# ESM_ESM_52D00000h register map
Vendor: Texas Instruments
Peripheral module from a debugger description file (folder AM263P).
Registers are 32-bit, access not given, reset 0x0 unless marked. A register's access mark holds for its fields unless they carry their own. Offsets are as the file gives them; lines under a group give offsets from that group; [hi:lo] are bit positions; {n}, {i} and the like mark numbered series; 'fields as' and 'values as' point back to an identical list; <NAME> marks a mode.

## ESM
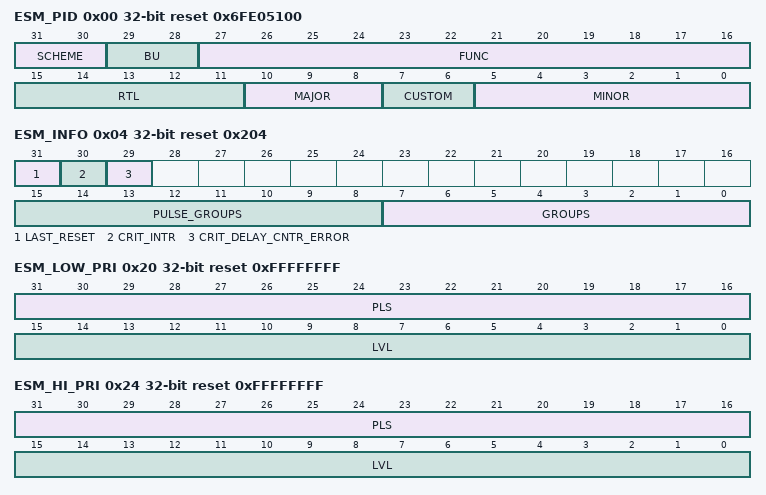
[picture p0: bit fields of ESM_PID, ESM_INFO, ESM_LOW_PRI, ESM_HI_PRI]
0x00 ESM_PID ro reset 0x6FE05100 — The Revision Register contains the major and minor revisions for the module.
  [31:30] SCHEME — PID register scheme
  [29:28] BU — Business Unit: 10 = Processors
  [27:16] FUNC — Module ID
  [15:11] RTL — RTL revision. Will vary depending on release.
  [10:8] MAJOR — Major revision
  [7:6] CUSTOM
  [5:0] MINOR — Minor revision
0x04 ESM_INFO ro reset 0x204 — The Info Register gives the configuration Inforrmation of this ESM.
  [31] LAST_RESET — Indicates the Source of the last Reset
  [30] CRIT_INTR — Indicates if the critical priority interrupt output has asserted
  [29] CRIT_DELAY_CNTR_ERROR — Indicates if a bit error has occurred in the critical priority interrupt delay counter
  [15:8] PULSE_GROUPS — Number of Pulse Error Groups
  [7:0] GROUPS — Total number of Error Groups
0x08 ESM_EN rw — The Global Enable Register has the master interrupt mask.
  [3:0] KEY — Global Enable. This field is a global mask to all interrupts. It is reset by the warm reset. The purpose is to leave all of the raw status and per-interrupt enable bits alone so that, after a warm reset, software may observe the state of the ESM before the warm reset and try to debug what may have caused the reset. 0x0: All events are disabled 0xF: All events are enabled All others are invalid
0x0C ESM_SFT_RST wo — The Global Soft Reset Register controls the global clear for raw status and enables.
  [3:0] KEY — Global Soft Reset. Writing to this field can cause all of the raw status and all enables to be cleared. This can be used to reset the ESM state after debugging because of a warm reset. Write: 0xF: Clear all raw status and enable bits All others no effect Read: Always read as 0x0
0x10 ESM_ERR_RAW — Raw Status/Set Register for Configuration Errors.
  [3:0] STS — This is the raw status for config errors. This is the raw status for errors in the configuration for Group N. This field is only reset by a Power-On-Reset and not by warm reset. A global soft reset will set this field to 0 Read: 0x0:Inactive 0x1:Active/Pending Write 0x1 to set event raw status Bits associated with groups that are not implemented in a certain configuration are Reserved, Read as 0 and writes will have no effect. (access R/W1TS)
0x14 ESM_ERR_STS — Config Error Enable and Clear Register.
  [3:0] MSK — This is the masked status/clear for config errors. This is the masked status for errors in the configuration for Group N. This field is only reset by a Power-On-Reset (not warm reset). A global soft reset will set this field to 0. Read: 0x0:Inactive 0x1:Active/Pending and Enabled Write 0x1 to clear event raw status. Bits associated with groups that are not implemented in a certain configuration are Reserved, Read as 0 and writes will have no effect. (access R/W1TC)
0x18 ESM_ERR_EN_SET — Config Error Enable Set Register.
  [3:0] MSK — This is the mask enable set for config errors. This is the mask enable for errors in the configuration for Group N. If the corresponding bit and the global_enable are set, then then interrupt is unmasked. This field is only reset by a Power-On-Reset (not warm reset). A global soft reset will set this field to 0. Read: 0x0:Disabled 0x1:Enabled Write 1'b1 to set enable Bits associated with groups that are not implemented in a certain configuration are Reserved, Read as 0 and writes will have no effect. (access R/W1TS)
0x1C ESM_ERR_EN_CLR — Config Error Interrupt Enabled Clear register.
  [3:0] MSK — This is the mask enable clear for config errors. This is the mask clear for errors in the configuration for Group N. If the corresponding bit and the global_enable are set, then then interrupt is unmasked. This field is only reset by a Power-On-Reset (not warm reset). A global soft reset will set this field to 0. Read: 0x0:Disabled 0x1:Enabled Write 1'b1 to clear enable Bits associated with groups that are not implemented in a certain configuration are Reserved, Read as 0 and writes will have no effect. (access R/W1TC)
0x20 ESM_LOW_PRI ro reset 0xFFFFFFFF — Shows which is the highest priority outstanding low priority interrupt.
  [31:16] PLS — This is the highest priority outstanding low priority pulse interrupt. Indicates what the highest priority Low Priority interrupt caused by a pulse number is. The lowest event has the highest priority. i.e. if Global Events 0, 1, 2, 3, and 4 are pending, and Global Event 0, and are configured for High Priority while Global Events 2, 3, and 4 are configured for Low Priority, then the value of this field will be 0x2. value of all ones (0xFFFF) indicates that there are no low priority interrupts pending. This field is updated whenever a new, higher priority event comes in. Software cannot read this field multiple times during an interrupt service routine to keep track of which interrupt is being serviced, because this field may have been updated with a higher priority event.
  [15:0] LVL — This is the highest priority outstanding low priority level interrupt. Indicates what the highest priority Low Priority interrupt caused by a level number is. The lowest event has the highest priority. i.e. if Global Events 0, 1, 2, 3, and 4 are pending, and Global Event 0, and are configured for High Priority while Global Events 2, 3, and 4 are configured for Low Priority, then the value of this field will be 0x2. value of all ones (0xFFFF) indicates that there are no low priority interrupts pending. This field is updated whenever a new, higher priority event comes in. Software cannot read this field multiple times during an interrupt service routine to keep track of which interrupt is being serviced, because this field may have been updated with a higher priority event.
0x24 ESM_HI_PRI ro reset 0xFFFFFFFF — Shows which is the highest priority outstanding high priority interrupt.
  [31:16] PLS — This is the highest priority outstanding high priority pulse interrupt. Indicates what the highest priority High Priority interrupt caused by a pulse number is. The lowest event has the highest priority. i.e. if Global Events 0, 1, 2, 3, and 4 are pending, and Global Event 0, and are configured for High Priority while Global Events 2, 3, and 4 are configured for Low Priority, then the value of this field will be 0x2. value of all ones (0xFFFF) indicates that there are no low priority interrupts pending. This field is updated whenever a ew, higher priority event comes in. Software cannot read this field multiple times during an interrupt service routine to keep track of which interrupt is being serviced, because this field may have been updated with a higher priority event.
  [15:0] LVL — This is the highest priority outstanding high priority level interrupt. Indicates what the highest priority High Priority interrupt caused by a level number is. The lowest event has the highest priority. i.e. if Global Events 0, 1, 2, 3, and 4 are pending, and Global Event 0, and are configured for High Priority while Global Events 2, 3, and 4 are configured for Low Priority, then the value of this field will be 0x2. value of all ones (0xFFFF) indicates that there are no low priority interrupts pending. This field is updated whenever a ew, higher priority event comes in. Software cannot read this field multiple times during an interrupt service routine to keep track of which interrupt is being serviced, because this field may have been updated with a higher priority event.
0x28 ESM_LOW ro — Shows which groups have oustanding low priority interrupts.
  [31:0] STS — This is the raw status for config errors. Indicates which Event Groups have one or more Low Priority interrupts pending. This register is bit oriented where bit 0 is for Event Group 0, bit 1 is for Event Group 1, etc (bit N is for Event Group N).
0x2C ESM_HI ro — Shows which groups have oustanding high priority interrupts.
  [31:0] STS — This is the raw status for config errors. Indicates which Event Groups have one or more High Priority interrupts pending. This register is bit oriented where bit 0 is for Event Group 0, bit 1 is for Event Group 1, etc (bit N is for Event Group N).
0x30 ESM_EOI wo — End of Interrupt Register.
  [10:0] KEY — This is the interrupt being serviced. Writing the corresponding vector to this field will cause a reevaluation of interrupts. If, when the vector is written, there are still pending interrupts, a new pulse will be generated. 0x0: Configuration Error Interrupt 0x1: Low Priority Error Interrupt 0x2: High Priority Error Interrupt All other values are reserved(writes have no effect).
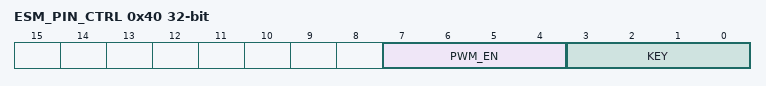
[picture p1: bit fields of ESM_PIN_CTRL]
0x40 ESM_PIN_CTRL rw — This register controls the error_pin_n output.
  [7:4] PWM_EN — PWM enable. PWM mode enable. This field should only be modified when the ESM is disabled, from the Global Enable register. This field is only reset by a Power-On-Reset (not warm reset). 0x0:Error output pin is a level 0xF:Error output pin is a PWM signal All other are invalid
  [3:0] KEY — Pin Control Key. This field controls behavior of the Error Pin. Note, during reset the field is 0x0, but the Error Pin is asserted (active low). Immediately after reset, the Error Pin de-asserts. This field is only reset by a Power-On-Reset (not warm reset). 0x0: Normal Mode - Error Pin will activate when an enabled Error Event occurs 0xA: Force Error Mode - Forces the Error Pin active. To clear the Error Pin (return to the ESM_IDLE state) write this field back to Normal Mode (Writing a CLEAR event will also work). You may only write to Force Error Mode while in IDLE. Attempting Force Error while in another state will have no effect 0x5 : CLEAR Event - generates a CLEAR event to the ESM state machine. Key will return to Normal Mode (0x0) on the next cycle. All Other Values - Normal Mode. Writing any of these values will have no effect. Reading any of these values indicate that one or more bits have experienced a single event upset and software should write the field back to 0x0. The ESM will continue to operate in Normal Mode
0x44 ESM_PIN_STS ro — This register reflects the status of the error_pin_n output.
  [0] VAL — Value of the error_pin_n. This field indicates the status of the Error Pin as looped back from the I/O. This field reflects the state of SAFETY_ERRORn I/O. 0x1 - De-Asserted 0x0 - Asserted Note, while in reset the error pin is actually active (asserted low), but goes inactive immediately after the de-assertion of Power-on-Reset. Hence, the value that will be read after Power-on-Reset is 1, but may be 0 after a warm reset.
0x48 ESM_PIN_CNTR ro — This register shows the current value of the error pin counter.
  [23:0] COUNT — Current Counter Value. This field indicates the current value of the Time Interval Counter. Register is reloaded to the counter preload value on entry to the ESM_ERROR state from ESM_IDLE and counts down by one per clock cycle. Once the counter has reached 0, the Minimum Time Interval has expired. This field is only reset by a Power-On-Reset (not warm reset).
0x4C ESM_PIN_CNTR_PRE rw — This register contains the value that is loaded in to the Error Counter.
  [23:0] COUNT — Counter Pre-Load Value. This is the value that will be loaded in to the counter field of the Error Pin Counter Value Register whenever the ESM enters the ESM_ERROR state from ESM_IDLE. This field is only reset by a Power-On-Reset (not warm reset).
0x50 ESM_PWMH_PIN_CNTR ro — This register shows the current value of the error pin PWM high counter.
  [23:0] COUNT — Current Counter Value. This field indicates the current value of the PWM High Time Interval Counter. The reset value is the 24'h0186A0. If pwm_en is set to PWM mode, then this register is enabled. This register is reloaded to the PWM high PIN_CNTR_PRE.count value when the error output pin toggles high. It will decrement by 1 each cycle when the error output pin is high. Once the counter has reached 0, the error output pin will toggle low. This field is only reset by a Power-On-Reset (not warm reset). A global soft reset will set this field to 24'h0186A0.
0x54 ESM_PWMH_PIN_CNTR_PRE rw — This register contains the value that is loaded in to the Error PWM High Counter.
  [23:0] COUNT — Counter Pre-Load Value. This is the value that will be loaded in to the counter field of the Error Pin PWM High Counter Value Register whenever the error output pin toggles high. This field is only reset by a Power-On-Reset (not warm reset). A global soft reset will set this field to 24'h0186A0.
0x58 ESM_PWML_PIN_CNTR ro — This register shows the current value of the error pin PWM low counter.
  [23:0] COUNT — Current Counter Value. This field indicates the current value of the PWM Low Time Interval Counter. The reset value is the 24'h0186A0. If pwm_en is set to PWM mode, then this register is enabled. This register is reloaded to the PWM low counter_preload value when the error output pin toggles low. It will decrement by 1 each cycle when the error output pin is low. Once the counter has reached 0, the error output pin will toggle high. This field is only reset by a Power-On-Reset (not warm reset). A global soft reset will set this field to 24'h0186A0.
0x5C ESM_PWML_PIN_CNTR_PRE rw — This register contains the value that is loaded in to the Error PWM Low Counter.
  [23:0] COUNT — Counter Pre-Load Value. This is the value that will be loaded in to the counter field of the Error Pin PWM Low Counter Value Register whenever the error output pin toggles low. This field is only reset by a Power-On-Reset (not warm reset). A global soft reset will set this field to 24'h0186A0.
0x60 ESM_CRIT_DELAY_CNTR ro — This register shows the current value of the Critical Priority Interrupt Delay Counter.
  [31:0] COUNT — Current Counter Value. This field indicates the current value of the Critical Priority Interrupt Delay Counter. The reset value is the crit_delay_cntr_ipcfg tie-off. This register decrements by 1 each cycle there is an input error event asserted which can influence the critical priority interrupt. This register is reloaded to the Critical Priority Interrupt Delay counter_preload value if there are no critical priority interrupt influential events left and the register count value is still non-zero. Once the counter has reached 0, the critical priority interrupt outputs will assert/pulse. A warm reset or global soft reset will set this field to crit_delay_cntr_ipcfg.
0x64 ESM_CRIT_DELAY_CNTR_PRE rw — This register contains the value that is loaded into the Critical Priority Interrupt Delay Counter.
  [31:0] COUNT — Counter Pre-Load Value. This is the value that will be loaded in to the counter field of the Critical Priority Interrupt Delay Counter Value Register whenever there are no critical priority interrupt influential events left and the register count value is still non-zero. The default value is determined by a module tie-off crit_delay_cntr_ipcfg. If an immediate, no-delayed interrupt is needed, the tieoff value can be assigned to 0 or software can program the field to be 0. Note that the ESM clock is required to be active and that the ESM still requires 2-3 cycles to observe aninput error event. This field is only reset by a Power-On-Reset (not warm reset). A global soft reset will set this field to crit_delay_cntr_ipcfg.
0x400 ESM_PCR_GENERATED_MEMORY_MAP_ERR_GRP_RAW_j — Raw Status/Set Register for Group A Errors
  [31:0] STS — This is the raw status/set for errors Group A. This is the raw status of the events in group N. Each bit corresponds to event Q where Q = N*32+Bit (Example: bit 0 is event N*32+0, bit 1 is N*32 + 1 etc). For Level events, the raw status is the event input synchronized to the ESM clock and stored in a multi-bit (for redundancy) internal register. For Pulse events, the raw status is multi-bit (for redundancy) internal register that is set when two of the three edge detection circuits on the redundant event capture a rising edge. This field is only reset by a Power-On-Reset (not warm reset). A global soft reset will set this field to 0. Read: 0x0: Inactive 0x1: Active/Pending Write 0x1 to set interrupt raw status. (access R/W1TS)
0x404 ESM_PCR_GENERATED_MEMORY_MAP_ERR_GRP_STS_j — Error Enable and Clear Register
  [31:0] MSK — This is the masked status/clear for errors in Group A. This is the masked status of the events in group N. Each bit corresponds to event Q where Q = N*32+Bit (Example: bit 0 is event N*32+0, bit 1 is N*32 + 1 etc...). This field is only reset by a Power-On-Reset (not warm reset). A global soft reset will set this field to 0. Read: 0x0: Inactive 0x1: Active/Pending Write 0x1 to clear interrupt raw status. (access R/W1TC)
0x408 ESM_PCR_GENERATED_MEMORY_MAP_ERR_GRP_INTR_EN_SET_j — Level Error Enable Set Register
  [31:0] MSK — This is the mask enable set for errors in Group A. This field is used to enable the mask of events in group N. Each bit corresponds to event Q where Q = N*32+Bit. If the corresponding bit and the global_enable are set, then then interrupt is unmasked. This field is only reset by a Power-On-Reset (not warm reset). A global soft reset will set this field to 0. Read: 0x0: Disabled 0x1: Enabled Write 0x1 to set enable (access R/W1TS)
0x40C ESM_PCR_GENERATED_MEMORY_MAP_ERR_GRP_INTR_EN_CLR_j — Level Error Interrupt Enabled Clear register
  [31:0] MSK — This is the mask enable clear for errors in Group A. This field is used to disable the mask of events in group N. Each bit corresponds to event Q where Q = N*32+Bit. If the corresponding bit and the global_enable are set, then then interrupt is unmasked. This field is only reset by a Power-On-Reset (not warm reset). A global soft reset will set this field to 0. Read: 0x0: Disabled 0x1: Enabled Write 1'b1 to clear enable (access R/W1TC)
0x410 ESM_PCR_GENERATED_MEMORY_MAP_ERR_GRP_INT_PRIO_j rw — Level Error Interrupt Priority register
  [31:0] MSK — This is interrupt priority for errors in Group A. This field is used to indicate which interrupt the corresponding event influences (if enabled) for event group N. Each bit corresponds to event Q where Q = N*32+Bit. This field is only reset by a Power-On-Reset (not warm reset). A global soft reset will set this field to 0. 0x0 - Low Priority Interrupt 0x1 - High Priority Interrupt
0x414 ESM_PCR_GENERATED_MEMORY_MAP_ERR_GRP_PIN_EN_SET_j — Error Pin Enabled Set register
  [31:0] MSK — This is the error pin influence enable set for errors in Group A. This field is used to enable the mask of events in group N. Each bit corresponds to event Q where Q = N*32+Bit. This field is only reset by a Power-On-Reset (not warm reset). A global soft reset will set this field to 0. Read: 0x0: Disabled 0x1: Enabled Write 1'b1 to set enable (access R/W1TS)
0x418 ESM_PCR_GENERATED_MEMORY_MAP_ERR_GRP_PIN_EN_CLR_j — Error Pin Enabled Clear register
  [31:0] MSK — This is the error pin influence enable clear for errors in Group A. This field is used to enable the mask of events in group N. Each bit corresponds to event Q where Q = N*32+Bit. This field is only reset by a Power-On-Reset (not warm reset). A global soft reset will set this field to 0. Read: 0x0: Disabled 0x1: Enabled Write 1'b1 to clear enable (access R/W1TC)
0x800 ESM_PCR_GENERATED_MEMORY_MAP_ERR_EXT_GRP_CRIT_EN_SET_j — Level Critical Priority Interrupt Enabled Clear register
  [31:0] MSK — This is the critical priority interrupt influence enable set for errors in Group A. This field is used to enable the mask of events in group N. Each bit corresponds to event Q where Q = N*32+Bit (Example: bit 0 is event N*32+0, bit 1 is N*32 + 1 etc�) This field is only reset by a Power-On-Reset (not warm reset). A global soft reset will set this field to 0. Read: 0x0: Disabled 0x1: Enabled Write: 0x0: No effect 0x1: Set Enable. Corresponding event, when set, will count as a pending event towards generating a critical priority interrupt if not cleared by cycle count in the critical priority interrupt delay counter register. (access R/W1TS)
0x804 ESM_PCR_GENERATED_MEMORY_MAP_ERR_EXT_GRP_CRIT_EN_CLR_j — Level Critical Priority Interrupt Enabled Clear register
  [31:0] MSK — This is the critical priority interrupt influence enable clear for errors in Group A. This field is used to enable the mask of events in group N. Each bit corresponds to event Q where Q = N*32+Bit (Example: bit 0 is event N*32+0, bit 1 is N*32 + 1 etc�) This field is only reset by a Power-On-Reset (not warm reset). A global soft reset will set this field to 0. Read: 0x0: Disabled 0x1: Enabled Write: 0x0: No effect 0x1: Clear Enable. Corresponding events will no longer count as pending events towards generating a critical priority interrupt. (access R/W1TC)
